# STM32WLE4C8U6 register map
File version: 1.0
Registers are 32-bit, access not given, reset 0x0 unless marked. A register's access mark holds for its fields unless they carry their own. Offsets are from the block's base; [hi:lo] are bit positions; {n}, {i} and the like mark numbered series.

## GPIO
Base 0x48000400
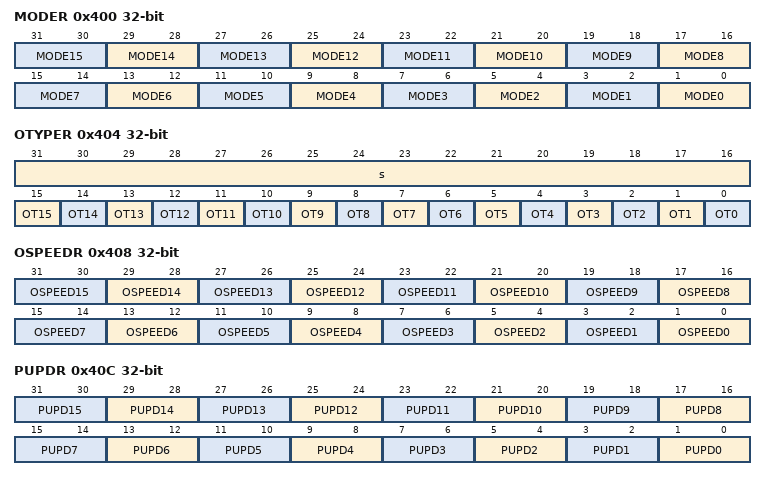
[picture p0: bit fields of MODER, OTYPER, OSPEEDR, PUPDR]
0x400 MODER
  [2n+1:2n] MODE{n} (n=0..15)
0x404 OTYPER
  [31:16] s, [n] OT{n} (n=0..15)
0x408 OSPEEDR
  [2n+1:2n] OSPEED{n} (n=0..15)
0x40C PUPDR
  [2n+1:2n] PUPD{n} (n=0..15)
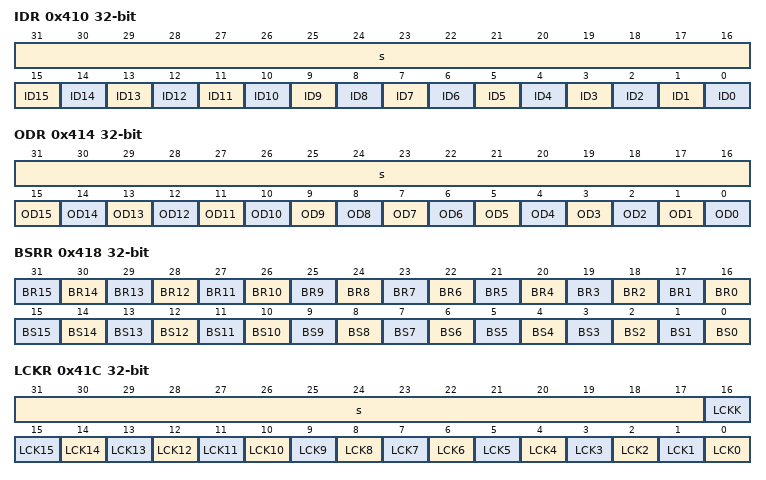
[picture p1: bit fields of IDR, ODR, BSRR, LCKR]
0x410 IDR
  [31:16] s, [n] ID{n} (n=0..15)
0x414 ODR
  [31:16] s, [n] OD{n} (n=0..15)
0x418 BSRR
  [n+16] BR{n} (n=0..15), [n] BS{n} (n=0..15)
0x41C LCKR
  [31:17] s, [16] LCKK, [n] LCK{n} (n=0..15)
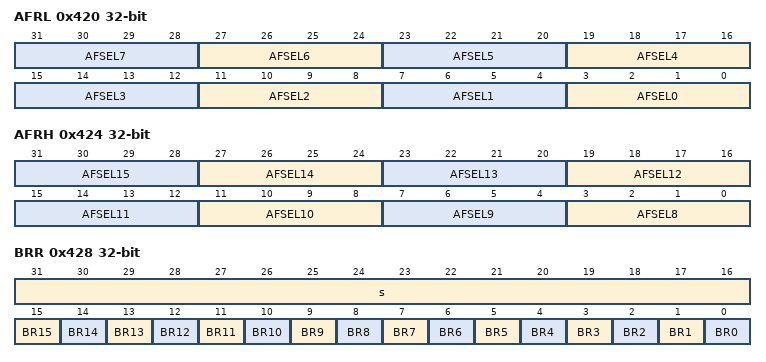
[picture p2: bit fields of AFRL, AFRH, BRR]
0x420 AFRL
  [4n+3:4n] AFSEL{n} (n=0..7)
0x424 AFRH
  [4n-29:4n-32] AFSEL{n} (n=8..15)
0x428 BRR
  [31:16] s, [n] BR{n} (n=0..15)
